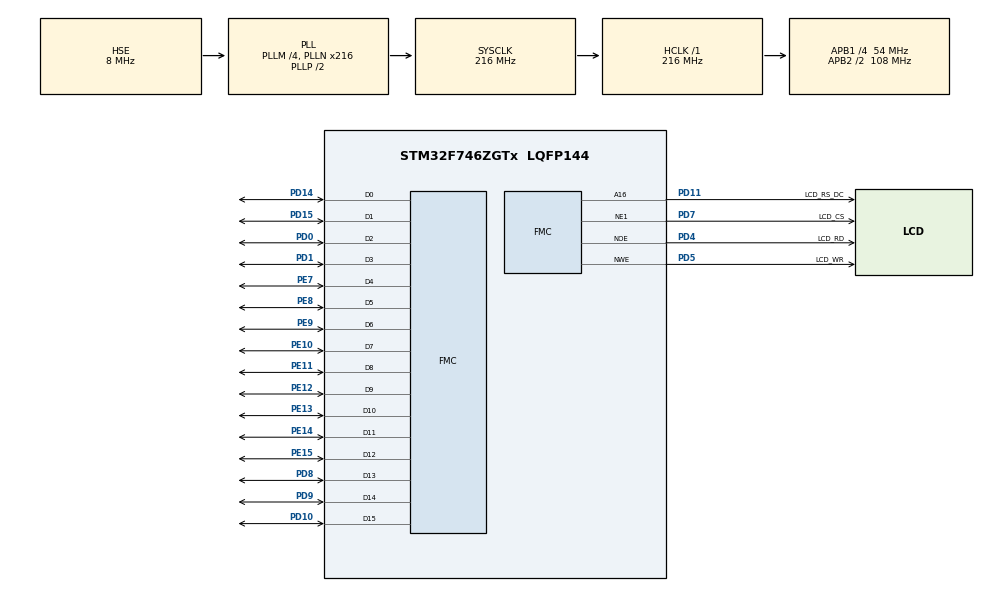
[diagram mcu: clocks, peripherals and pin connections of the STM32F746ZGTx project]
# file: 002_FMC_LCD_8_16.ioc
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CORTEX_M7.ART_ACCELERATOR_ENABLE=0
CORTEX_M7.AccessPermission-Cortex_Memory_Protection_Unit_Region0_Settings=MPU_REGION_FULL_ACCESS
CORTEX_M7.AccessPermission_S-Cortex_Memory_Protection_Unit_Region1_Settings_S=MPU_REGION_FULL_ACCESS
CORTEX_M7.BaseAddress-Cortex_Memory_Protection_Unit_Region0_Settings=0x60000000
CORTEX_M7.BaseAddress_S-Cortex_Memory_Protection_Unit_Region1_Settings_S=0x60000000
CORTEX_M7.CPU_DCache=Enabled
CORTEX_M7.CPU_ICache=Enabled
CORTEX_M7.DisableExec_S-Cortex_Memory_Protection_Unit_Region1_Settings_S=MPU_INSTRUCTION_ACCESS_ENABLE
CORTEX_M7.Enable-Cortex_Memory_Protection_Unit_Region0_Settings=MPU_REGION_ENABLE
CORTEX_M7.Enable_S-Cortex_Memory_Protection_Unit_Region1_Settings_S=MPU_REGION_ENABLE
CORTEX_M7.Enable_S-Cortex_Memory_Protection_Unit_Region2_Settings_S=__NULL
CORTEX_M7.FlashInterface=AXI_Enabled
CORTEX_M7.IsBufferable-Cortex_Memory_Protection_Unit_Region0_Settings=MPU_ACCESS_NOT_BUFFERABLE
CORTEX_M7.IsBufferable_S-Cortex_Memory_Protection_Unit_Region1_Settings_S=MPU_ACCESS_BUFFERABLE
CORTEX_M7.IsCacheable-Cortex_Memory_Protection_Unit_Region0_Settings=MPU_ACCESS_NOT_CACHEABLE
CORTEX_M7.IsCacheable_S-Cortex_Memory_Protection_Unit_Region1_Settings_S=MPU_ACCESS_CACHEABLE
CORTEX_M7.IsShareable-Cortex_Memory_Protection_Unit_Region0_Settings=MPU_ACCESS_SHAREABLE
CORTEX_M7.IsShareable_S-Cortex_Memory_Protection_Unit_Region1_Settings_S=MPU_ACCESS_SHAREABLE
CORTEX_M7.MPU_Control=MPU_PRIVILEGED_DEFAULT
CORTEX_M7.PREFETCH_ENABLE=0
CORTEX_M7.Size-Cortex_Memory_Protection_Unit_Region0_Settings=MPU_REGION_SIZE_512KB
CORTEX_M7.Size_S-Cortex_Memory_Protection_Unit_Region1_Settings_S=MPU_REGION_SIZE_4GB
CORTEX_M7.TypeExtField_S-Cortex_Memory_Protection_Unit_Region1_Settings_S=MPU_TEX_LEVEL0
CORTEX_M7.default_mode_Activation=0
FMC.WriteFifo1=FMC_WRITE_FIFO_ENABLE
Mcu.Family=STM32F7
Mcu.Name=STM32F746ZGTx
Mcu.Package=LQFP144
NVIC.PriorityGroup=NVIC_PRIORITYGROUP_4
PA13.Mode=Trace_Asynchronous_SW
PA13.Signal=SYS_JTMS-SWDIO
PA14.Mode=Trace_Asynchronous_SW
PA14.Signal=SYS_JTCK-SWCLK
PB3.Mode=Trace_Asynchronous_SW
PB3.Signal=SYS_JTDO-SWO
PC14/OSC32_IN.Mode=LSE-External-Oscillator
PC14/OSC32_IN.Signal=RCC_OSC32_IN
PC15/OSC32_OUT.Mode=LSE-External-Oscillator
PC15/OSC32_OUT.Signal=RCC_OSC32_OUT
PD0.Signal=FMC_D2_DA2
PD1.Signal=FMC_D3_DA3
PD10.Signal=FMC_D15_DA15
PD11.GPIO_Label=LCD_RS_DC
PD11.Signal=FMC_A16_CLE
PD14.Signal=FMC_D0_DA0
PD15.Signal=FMC_D1_DA1
PD4.GPIO_Label=LCD_RD
PD4.Signal=FMC_NOE
PD5.GPIO_Label=LCD_WR
PD5.Signal=FMC_NWE
PD7.GPIO_Label=LCD_CS
PD7.Mode=NorPsramChipSelect1_1
PD7.Signal=FMC_NE1
PD8.Signal=FMC_D13_DA13
PD9.Signal=FMC_D14_DA14
PE10.Signal=FMC_D7_DA7
PE11.Signal=FMC_D8_DA8
PE12.Signal=FMC_D9_DA9
PE13.Signal=FMC_D10_DA10
PE14.Signal=FMC_D11_DA11
PE15.Signal=FMC_D12_DA12
PE7.Signal=FMC_D4_DA4
PE8.Signal=FMC_D5_DA5
PE9.Signal=FMC_D6_DA6
PH0/OSC_IN.Mode=HSE-External-Clock-Source
PH0/OSC_IN.Signal=RCC_OSC_IN
PH1/OSC_OUT.Mode=HSE-External-Clock-Source
PH1/OSC_OUT.Signal=RCC_OSC_OUT
ProjectManager.HeapSize=0x200
ProjectManager.StackSize=0x400
ProjectManager.TargetToolchain=STM32CubeIDE
RCC.AHBFreq_Value=216000000
RCC.APB1CLKDivider=RCC_HCLK_DIV4
RCC.APB1Freq_Value=54000000
RCC.APB1TimFreq_Value=108000000
RCC.APB2CLKDivider=RCC_HCLK_DIV2
RCC.APB2Freq_Value=108000000
RCC.APB2TimFreq_Value=216000000
RCC.CortexFreq_Value=216000000
RCC.HCLKFreq_Value=216000000
RCC.HSE_VALUE=8000000
RCC.HSI_VALUE=16000000
RCC.PLLM=4
RCC.PLLN=216
RCC.PLLSourceVirtual=RCC_PLLSOURCE_HSE
RCC.PWR_Regulator_Voltage_Scale=PWR_REGULATOR_VOLTAGE_SCALE1
RCC.SYSCLKFreq_VALUE=216000000
RCC.SYSCLKSource=RCC_SYSCLKSOURCE_PLLCLK
RCC.USBFreq_Value=216000000
RCC.VCOOutputFreq_Value=432000000
SH.FMC_A16_CLE.0=FMC_A16,A16_1
SH.FMC_D0_DA0.0=FMC_D0,16b-d1
SH.FMC_D10_DA10.0=FMC_D10,16b-d1
SH.FMC_D11_DA11.0=FMC_D11,16b-d1
SH.FMC_D12_DA12.0=FMC_D12,16b-d1
SH.FMC_D13_DA13.0=FMC_D13,16b-d1
SH.FMC_D14_DA14.0=FMC_D14,16b-d1
SH.FMC_D15_DA15.0=FMC_D15,16b-d1
SH.FMC_D1_DA1.0=FMC_D1,16b-d1
SH.FMC_D2_DA2.0=FMC_D2,16b-d1
SH.FMC_D3_DA3.0=FMC_D3,16b-d1
SH.FMC_D4_DA4.0=FMC_D4,16b-d1
SH.FMC_D5_DA5.0=FMC_D5,16b-d1
SH.FMC_D6_DA6.0=FMC_D6,16b-d1
SH.FMC_D7_DA7.0=FMC_D7,16b-d1
SH.FMC_D8_DA8.0=FMC_D8,16b-d1
SH.FMC_D9_DA9.0=FMC_D9,16b-d1
SH.FMC_NOE.0=FMC_NOE,Lcd1
SH.FMC_NWE.0=FMC_NWE,Lcd1
board=custom

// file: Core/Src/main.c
/* USER CODE BEGIN Header */
/**
  ******************************************************************************
  * @file           : main.c
  * @brief          : Main program body
  ******************************************************************************
  * @attention
  *
  * Copyright (c) 2023 STMicroelectronics.
  * All rights reserved.
  *
  * This software is licensed under terms that can be found in the LICENSE file
  * in the root directory of this software component.
  * If no LICENSE file comes with this software, it is provided AS-IS.
  *
  ******************************************************************************
  */
/* USER CODE END Header */
#include "main.h"
#include "gpio.h"
#include "fmc.h"

/* USER CODE BEGIN Includes */
#include "../../loop/loop.h"
/* USER CODE END Includes */

void SystemClock_Config(void);
static void MPU_Config(void);

int main(void)
{

  /* MPU Configuration--------------------------------------------------------*/
  MPU_Config();

  /* Enable I-Cache---------------------------------------------------------*/
  SCB_EnableICache();

  /* Enable D-Cache---------------------------------------------------------*/
  SCB_EnableDCache();

  /* MCU Configuration--------------------------------------------------------*/

  /* Reset of all peripherals, Initializes the Flash interface and the Systick. */
  HAL_Init();

  /* Configure the system clock */
  SystemClock_Config();

  /* Initialize all configured peripherals */
  MX_GPIO_Init();
  MX_FMC_Init();

  /* Infinite loop */
  /* USER CODE BEGIN WHILE */
  setup();
  while (1)
  {
	  loop();
    /* USER CODE END WHILE */

  }
}

void SystemClock_Config(void)
{
  RCC_OscInitTypeDef RCC_OscInitStruct = {0};
  RCC_ClkInitTypeDef RCC_ClkInitStruct = {0};

  /** Configure LSE Drive Capability
  */
  HAL_PWR_EnableBkUpAccess();

  /** Configure the main internal regulator output voltage
  */
  __HAL_RCC_PWR_CLK_ENABLE();
  __HAL_PWR_VOLTAGESCALING_CONFIG(PWR_REGULATOR_VOLTAGE_SCALE1);

  /** Initializes the RCC Oscillators according to the specified parameters
  * in the RCC_OscInitTypeDef structure.
  */
  RCC_OscInitStruct.OscillatorType = RCC_OSCILLATORTYPE_HSE;
  RCC_OscInitStruct.HSEState = RCC_HSE_BYPASS;
  RCC_OscInitStruct.PLL.PLLState = RCC_PLL_ON;
  RCC_OscInitStruct.PLL.PLLSource = RCC_PLLSOURCE_HSE;
  RCC_OscInitStruct.PLL.PLLM = 4;
  RCC_OscInitStruct.PLL.PLLN = 216;
  RCC_OscInitStruct.PLL.PLLP = RCC_PLLP_DIV2;
  RCC_OscInitStruct.PLL.PLLQ = 2;
  if (HAL_RCC_OscConfig(&RCC_OscInitStruct) != HAL_OK)
  {
    Error_Handler();
  }

  /** Activate the Over-Drive mode
  */
  if (HAL_PWREx_EnableOverDrive() != HAL_OK)
  {
    Error_Handler();
  }

  /** Initializes the CPU, AHB and APB buses clocks
  */
  RCC_ClkInitStruct.ClockType = RCC_CLOCKTYPE_HCLK|RCC_CLOCKTYPE_SYSCLK
                              |RCC_CLOCKTYPE_PCLK1|RCC_CLOCKTYPE_PCLK2;
  RCC_ClkInitStruct.SYSCLKSource = RCC_SYSCLKSOURCE_PLLCLK;
  RCC_ClkInitStruct.AHBCLKDivider = RCC_SYSCLK_DIV1;
  RCC_ClkInitStruct.APB1CLKDivider = RCC_HCLK_DIV4;
  RCC_ClkInitStruct.APB2CLKDivider = RCC_HCLK_DIV2;

  if (HAL_RCC_ClockConfig(&RCC_ClkInitStruct, FLASH_LATENCY_7) != HAL_OK)
  {
    Error_Handler();
  }
}

/* MPU Configuration */

void MPU_Config(void)
{
  MPU_Region_InitTypeDef MPU_InitStruct = {0};

  /* Disables the MPU */
  HAL_MPU_Disable();

  /** Initializes and configures the Region and the memory to be protected
  */
  MPU_InitStruct.Enable = MPU_REGION_ENABLE;
  MPU_InitStruct.Number = MPU_REGION_NUMBER0;
  MPU_InitStruct.BaseAddress = 0x60000000;
  MPU_InitStruct.Size = MPU_REGION_SIZE_512KB;
  MPU_InitStruct.SubRegionDisable = 0x0;
  MPU_InitStruct.TypeExtField = MPU_TEX_LEVEL0;
  MPU_InitStruct.AccessPermission = MPU_REGION_FULL_ACCESS;
  MPU_InitStruct.DisableExec = MPU_INSTRUCTION_ACCESS_ENABLE;
  MPU_InitStruct.IsShareable = MPU_ACCESS_SHAREABLE;
  MPU_InitStruct.IsCacheable = MPU_ACCESS_NOT_CACHEABLE;
  MPU_InitStruct.IsBufferable = MPU_ACCESS_NOT_BUFFERABLE;

  HAL_MPU_ConfigRegion(&MPU_InitStruct);
  /* Enables the MPU */
  HAL_MPU_Enable(MPU_PRIVILEGED_DEFAULT);

}

void Error_Handler(void)
{
  __disable_irq();
  while (1)
  {
  }
}
